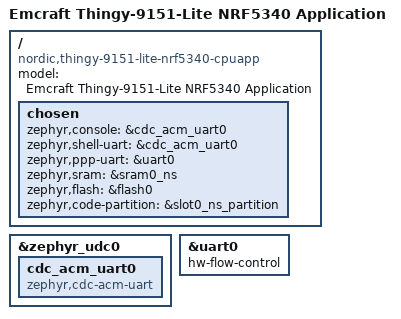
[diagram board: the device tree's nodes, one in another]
/*
 * Copyright (c) 2020 Nordic Semiconductor ASA
 *
 * SPDX-License-Identifier: Apache-2.0
 */

/dts-v1/;
#include <nordic/nrf5340_cpuappns_qkaa.dtsi>
#include "nrf5340_cpuapp_common.dtsi"

/ {
	model = "Emcraft Thingy-9151-Lite NRF5340 Application";
	compatible = "nordic,thingy-9151-lite-nrf5340-cpuapp";

	chosen {
		zephyr,console = &cdc_acm_uart0;
		zephyr,shell-uart = &cdc_acm_uart0;
		zephyr,ppp-uart = &uart0;
		zephyr,sram = &sram0_ns;
		zephyr,flash = &flash0;
		zephyr,code-partition = &slot0_ns_partition;
	};
};

&zephyr_udc0 {
	cdc_acm_uart0: cdc_acm_uart0 {
		compatible = "zephyr,cdc-acm-uart";
	};
};

&uart0 {
	status = "okay";
	hw-flow-control;
};
